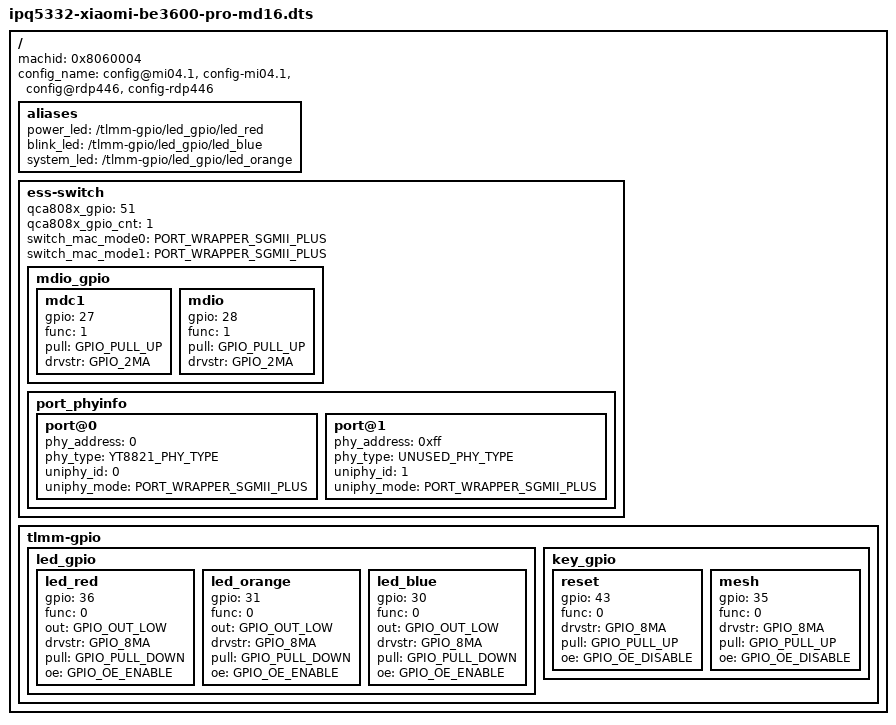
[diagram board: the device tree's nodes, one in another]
/*
 * Copyright (c) 2016-2019, The Linux Foundation. All rights reserved.
 *
 * Copyright (c) 2022-2023 Qualcomm Innovation Center, Inc. All rights reserved.
 *
 * This program is free software; you can redistribute it and/or modify
 * it under the terms of the GNU General Public License version 2 and
 * only version 2 as published by the Free Software Foundation.
 *
 * This program is distributed in the hope that it will be useful,
 * but WITHOUT ANY WARRANTY; without even the implied warranty of
 * MERCHANTABILITY or FITNESS FOR A PARTICULAR PURPOSE.  See the
 * GNU General Public License for more details.
 */

/dts-v1/;
#include "ipq5332-mi04.1.dts"
/ {
	machid = <0x8060004>;
	config_name = "config@mi04.1", "config-mi04.1", "config@rdp446", "config-rdp446";

	aliases {
		/delete-property/ mmc;
		power_led = "/tlmm-gpio/led_gpio/led_red";
		blink_led = "/tlmm-gpio/led_gpio/led_blue";
		system_led = "/tlmm-gpio/led_gpio/led_orange";
	};

	ess-switch {
		/delete-property/ napa_gpio;
		/delete-property/ napa_gpio_cnt;
		/delete-property/ qca8084_switch_enable;
		qca808x_gpio = <51>;
		qca808x_gpio_cnt = <1>;
		switch_mac_mode0 = <PORT_WRAPPER_SGMII_PLUS>;
		switch_mac_mode1 = <PORT_WRAPPER_SGMII_PLUS>;

		mdio_gpio {
			mdc1 {
				gpio = <27>;
				func = <1>;
				pull = <GPIO_PULL_UP>;
				drvstr = <GPIO_2MA>;
			};
			mdio {
				gpio = <28>;
				func = <1>;
				pull = <GPIO_PULL_UP>;
				drvstr = <GPIO_2MA>;
			};
		};

		port_phyinfo {
			port@0 {
				phy_address = <0>;
				phy_type = <YT8821_PHY_TYPE>;
				uniphy_id = <0>;
				uniphy_mode = <PORT_WRAPPER_SGMII_PLUS>;
			};
			port@1 {
				phy_address = <0xff>;
				phy_type = <UNUSED_PHY_TYPE>;
				uniphy_id = <1>;
				uniphy_mode = <PORT_WRAPPER_SGMII_PLUS>;
			};
		};
		/delete-node/ qca8084_swt_info;
	};

	tlmm-gpio {
		led_gpio {
			led_red {
				gpio = <36>;
				func = <0>;
				out = <GPIO_OUT_LOW>;
				drvstr = <GPIO_8MA>;
				pull = <GPIO_PULL_DOWN>;
				oe = <GPIO_OE_ENABLE>;
			};
			led_orange {
				gpio = <31>;
				func = <0>;
				out = <GPIO_OUT_LOW>;
				drvstr = <GPIO_8MA>;
				pull = <GPIO_PULL_DOWN>;
				oe = <GPIO_OE_ENABLE>;
			};
			led_blue {
				gpio = <30>;
				func = <0>;
				out = <GPIO_OUT_LOW>;
				drvstr = <GPIO_8MA>;
				pull = <GPIO_PULL_DOWN>;
				oe = <GPIO_OE_ENABLE>;
			};
		};
		key_gpio {
			reset {
				gpio = <43>;
				func = <0>;
				drvstr = <GPIO_8MA>;
				pull = <GPIO_PULL_UP>;
				oe = <GPIO_OE_DISABLE>;
			};
			mesh {
				gpio = <35>;
				func = <0>;
				drvstr = <GPIO_8MA>;
				pull = <GPIO_PULL_UP>;
				oe = <GPIO_OE_DISABLE>;
			};
		};
	};
};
